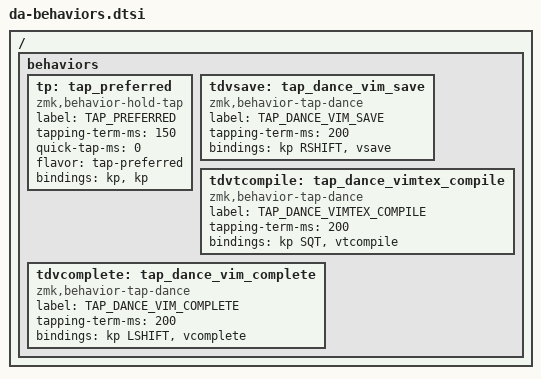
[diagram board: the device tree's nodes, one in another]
  
/ {

    behaviors {

      // Implements tap preferred behaviour
      tp: tap_preferred {
        compatible = "zmk,behavior-hold-tap";
        label = "TAP_PREFERRED";
        #binding-cells = <2>;
        tapping-term-ms = <150>;
        quick-tap-ms = <0>;
        flavor = "tap-preferred";
        bindings = <&kp>, <&kp>;
      }; 
      
      // Hold for right shift, 
      // Tap twice for saving in vim: Esc :w Enter
      tdvsave: tap_dance_vim_save {
           compatible = "zmk,behavior-tap-dance";
           label = "TAP_DANCE_VIM_SAVE";
           #binding-cells = <0>;
           tapping-term-ms = <200>;
           bindings = <&kp RSHIFT>, <&vsave>;
      };

      // Tap once for '
      // Tap twice for saving and compiling in vimtex: Esc :wq Space l l 
      tdvtcompile: tap_dance_vimtex_compile {
           compatible = "zmk,behavior-tap-dance";
           label = "TAP_DANCE_VIMTEX_COMPILE";
           #binding-cells = <0>;
           tapping-term-ms = <200>;
           bindings = <&kp SQT>, <&vtcompile>;
      };
        
      // Hold for left shift, 
      // Tap twice to trigger vim completion
      tdvcomplete: tap_dance_vim_complete {
           compatible = "zmk,behavior-tap-dance";
           label = "TAP_DANCE_VIM_COMPLETE";
           #binding-cells = <0>;
           tapping-term-ms = <200>;
           bindings = <&kp LSHIFT>, <&vcomplete>;
      };
      
    };

};
